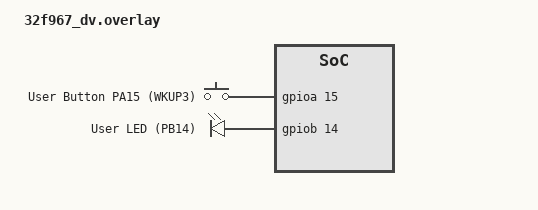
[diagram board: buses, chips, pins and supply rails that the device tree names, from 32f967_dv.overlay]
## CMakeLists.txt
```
# SPDX-License-Identifier: Apache-2.0
cmake_minimum_required(VERSION 3.20.0)

set(ZEPHYR_EXTRA_MODULES ${CMAKE_CURRENT_SOURCE_DIR}/../..)
include(${CMAKE_CURRENT_SOURCE_DIR}/../../cmake/compat_overlays.cmake)

find_package(Zephyr REQUIRED HINTS $ENV{ZEPHYR_BASE})
project(elan_pw_saving)

target_sources(app PRIVATE src/main.c)
```

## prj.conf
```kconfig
# Power management
CONFIG_PM=y
CONFIG_PM_DEVICE=y
CONFIG_POWEROFF=y

# GPIO
CONFIG_GPIO=y

# Logging
CONFIG_LOG=y
CONFIG_LOG_DEFAULT_LEVEL=3
CONFIG_LOG_BUFFER_SIZE=8192

# Set PM module (pm_em32) log level to DBG to see pm_state_set() traces
CONFIG_PM_LOG_LEVEL_DBG=y

# Set GPIO driver log level to DBG to see em32_pwr_wkup_pin_cfg_pupd() traces
CONFIG_GPIO_LOG_LEVEL_DBG=y

# SOC log level DBG
CONFIG_SOC_LOG_LEVEL_DBG=y

# EM32 wakeup pins support
CONFIG_EM32_WKUP_PINS=y
```

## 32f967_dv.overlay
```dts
/*
 * elan_pw_saving overlay for 32f967_dv
 *
 * Wakeup source: PA15 (WKUP3) — rising edge (GPIO_ACTIVE_HIGH)
 * No PA6 configuration — only PA15 is used for wakeup.
 */

#include <elan/32f967_dv_priv.dtsi>

/ {
	aliases {
		sw0 = &button0;
		led0 = &led0;
	};

	gpio_keys {
		compatible = "gpio-keys";
		status = "okay";

		/* PA15 — WKUP3, rising edge wakeup
		 * GPIO_PULL_DOWN (0x02) + GPIO_ACTIVE_HIGH (default, no flag)
		 * EM32_GPIO_WKUP (0x0100) = wakeup source
		 */
		button0: button_0 {
			gpios = <&gpioa 15 (GPIO_PULL_DOWN | GPIO_ACTIVE_HIGH)>;
			label = "User Button PA15 (WKUP3)";
		};
	};

	leds {
		compatible = "gpio-leds";
		status = "okay";

		led0: led_0 {
			gpios = <&gpiob 14 GPIO_ACTIVE_HIGH>;
			label = "User LED (PB14)";
		};
	};
};

&gpioa {
	status = "okay";
	wakeup-source;
};

&gpiob {
	status = "okay";
};
```

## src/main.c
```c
/*
 * SPDX-FileCopyrightText: 2026 ELAN Microelectronics Corp.
 * SPDX-License-Identifier: Apache-2.0
 *
 * Power saving test application for EM32F967 (32f967_dv)
 *
 * Uses pm_state_force() to enter PDSW2 (Standby1) mode automatically.
 * Wakeup source: PA15 (WKUP3, rising edge)
 *
 * Flow:
 *   1. Configure PA15 as input with pull-down + EM32_GPIO_WKUP flag
 *   2. Configure PB14 as LED output
 *   3. Wait 4 seconds
 *   4. Force PDSW2 (standby1) mode with RTC off
 *   5. Zephyr PM enters PDSW2 → WFI → system resets on PA15 rising edge
 *   6. Boot banner appears again
 */

#include <zephyr/kernel.h>
#include <zephyr/device.h>
#include <zephyr/drivers/gpio.h>
#include <zephyr/pm/pm.h>
#include <zephyr/pm/state.h>
#include <zephyr/dt-bindings/gpio/em32-gpio.h>

/* PA15 button (WKUP3, rising edge) */
static const struct gpio_dt_spec button = GPIO_DT_SPEC_GET(DT_ALIAS(sw0), gpios);

int main(void)
{
	int ret;

	if (!gpio_is_ready_dt(&button)) {
		printk("ERROR: button device %s is not ready\n", button.port->name);
		return -ENODEV;
	}

	printk("\nWake-up button is connected to %s pin %d (PA15, WKUP3, rising edge)\n",
	       button.port->name, button.pin);

	/*
	 * Configure PA15 as input + pull-down + EM32_GPIO_WKUP.
	 * The EM32_GPIO_WKUP flag (bit 8) registers PA15 as a wakeup source.
	 * GPIO_ACTIVE_HIGH → rising edge wakeup (PA15 goes HIGH on button press)
	 * GPIO_PULL_DOWN   → default state is LOW, button pulls HIGH
	 */
	ret = gpio_pin_configure_dt(&button, GPIO_INPUT | EM32_GPIO_WKUP);
	if (ret < 0) {
		printk("ERROR: failed to configure button: %d\n", ret);
		return ret;
	}

	printk("Will wait 4s before entering power saving (PDSW2)\n");

	k_busy_wait(4000000); /* 4 seconds */
	
	printk("Entering power saving mode (PDSW2 / Standby1)\n");
	printk("Press PA15 button (rising edge) to wake up and reset the system\n");

	/*
	 * Force PDSW2 (Standby1) mode with RTC off.
	 *
	 * pm_state_force() tells the Zephyr PM subsystem to enter the
	 * specified state on the next idle. When the kernel becomes idle,
	 * pm_system_suspend() → pm_state_set() → pm_handle_standby_modes()
	 * → pm_enter_standby1(false) → SLEEPDEEP + WFI.
	 *
	 * The WakeUp controller asserts SYSTEM RESET on PA15 rising edge.
	 * No IRQ handler needed — same as STM32 SHUTDOWN mode.
	 *
	 * substate_id = 2 → PDSW2 (Standby1, RTC off)
	 *   Matches power.c pm_handle_standby_modes() switch case:
	 *     case 2: mode = PDSW2; rtc_enable = false;
	 */
	struct pm_state_info pdsw2_rtc_off = {
		.state = PM_STATE_STANDBY,
		.substate_id = 2,
		.min_residency_us = 0,
		.exit_latency_us = 0,
	};

	if (!pm_state_force(0U, &pdsw2_rtc_off)) {
		printk("ERROR: pm_state_force() failed; PDSW2 not available\n");
		return -ENOTSUP;
	}

	printk("pm_state_force(PDSW2) succeeded — system will enter deep sleep on next idle\n");

	/*
	 * Let the kernel become idle so that pm_system_suspend() runs.
	 * k_sleep(K_FOREVER) puts the calling thread to sleep, making
	 * the system idle → PM kicks in → PDSW2 entered → WFI → RESET.
	 */
	k_sleep(K_FOREVER);

	/* Never reached — system resets on wakeup */
	CODE_UNREACHABLE;
	return 0;
}
```
